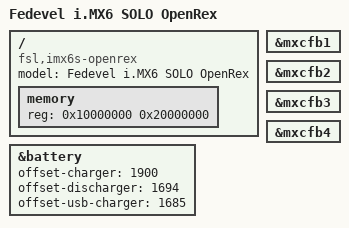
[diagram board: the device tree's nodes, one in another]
/*
 * Copyright 2012 Freescale Semiconductor, Inc.
 * Copyright 2011 Linaro Ltd.
 *
 * The code contained herein is licensed under the GNU General Public
 * License. You may obtain a copy of the GNU General Public License
 * Version 2 or later at the following locations:
 *
 * http://www.opensource.org/licenses/gpl-license.html
 * http://www.gnu.org/copyleft/gpl.html
 */

/dts-v1/;

#include "imx6dl.dtsi"
#include "imx6qdl-openrex.dtsi"

/ {
	model = "Fedevel i.MX6 SOLO OpenRex";
	compatible = "fsl,imx6s-openrex", "fsl,imx6dl";

	memory {
		reg = <0x10000000 0x20000000>; /* reg = <base_addr mem_size  (536870912 bytes => 512MB) */
        };

};

&battery {
	offset-charger = <1900>;
	offset-discharger = <1694>;
	offset-usb-charger = <1685>;
};


&mxcfb1 {
	status = "okay";
};

&mxcfb2 {
	status = "okay";
};

&mxcfb3 {
	status = "okay";
};

&mxcfb4 {
	status = "okay";
};
